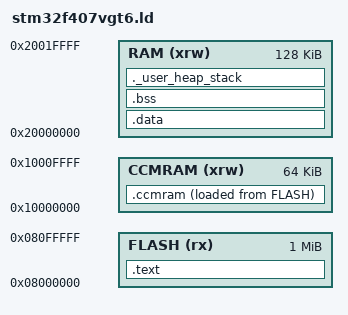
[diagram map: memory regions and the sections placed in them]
/*
******************************************************************************
**

**  File        : LinkerScript.ld
**
**  Author		: Auto-generated by System Workbench for STM32
**
**  Abstract    : Linker script for STM32F407VGTx series
**                1024Kbytes FLASH and 192Kbytes RAM
**
**                Set heap size, stack size and stack location according
**                to application requirements.
**
**                Set memory bank area and size if external memory is used.
**
**  Target      : STMicroelectronics STM32
**
**  Distribution: The file is distributed “as is,” without any warranty
**                of any kind.
**
*****************************************************************************
** @attention
**
** <h2><center>&copy; COPYRIGHT(c) 2019 STMicroelectronics</center></h2>
**
** Redistribution and use in source and binary forms, with or without modification,
** are permitted provided that the following conditions are met:
**   1. Redistributions of source code must retain the above copyright notice,
**      this list of conditions and the following disclaimer.
**   2. Redistributions in binary form must reproduce the above copyright notice,
**      this list of conditions and the following disclaimer in the documentation
**      and/or other materials provided with the distribution.
**   3. Neither the name of STMicroelectronics nor the names of its contributors
**      may be used to endorse or promote products derived from this software
**      without specific prior written permission.
**
** THIS SOFTWARE IS PROVIDED BY THE COPYRIGHT HOLDERS AND CONTRIBUTORS "AS IS"
** AND ANY EXPRESS OR IMPLIED WARRANTIES, INCLUDING, BUT NOT LIMITED TO, THE
** IMPLIED WARRANTIES OF MERCHANTABILITY AND FITNESS FOR A PARTICULAR PURPOSE ARE
** DISCLAIMED. IN NO EVENT SHALL THE COPYRIGHT HOLDER OR CONTRIBUTORS BE LIABLE
** FOR ANY DIRECT, INDIRECT, INCIDENTAL, SPECIAL, EXEMPLARY, OR CONSEQUENTIAL
** DAMAGES (INCLUDING, BUT NOT LIMITED TO, PROCUREMENT OF SUBSTITUTE GOODS OR
** SERVICES; LOSS OF USE, DATA, OR PROFITS; OR BUSINESS INTERRUPTION) HOWEVER
** CAUSED AND ON ANY THEORY OF LIABILITY, WHETHER IN CONTRACT, STRICT LIABILITY,
** OR TORT (INCLUDING NEGLIGENCE OR OTHERWISE) ARISING IN ANY WAY OUT OF THE USE
** OF THIS SOFTWARE, EVEN IF ADVISED OF THE POSSIBILITY OF SUCH DAMAGE.
**
*****************************************************************************
*/

/* Entry Point */
ENTRY(Reset_Handler)

/* Highest address of the user mode stack */
_estack = 0x20020000;    /* end of RAM */
/* Generate a link error if heap and stack don't fit into RAM */
_Min_Heap_Size = 0x200;      /* required amount of heap  */
_Min_Stack_Size = 0x400; /* required amount of stack */

/* Specify the memory areas */
MEMORY
{
RAM (xrw)      : ORIGIN = 0x20000000, LENGTH = 128K
CCMRAM (xrw)      : ORIGIN = 0x10000000, LENGTH = 64K
FLASH (rx)      : ORIGIN = 0x8000000, LENGTH = 1024K
}

/* Define output sections */
SECTIONS
{
    .text :
    {
        . = ALIGN(4);

        _text = .;

        KEEP(*(.isr_vector))

        . = ALIGN(4);
        
        *(.text .text* .gnu.linkonce.t.*)

        *(.glue_7t) *(.glue_7)

        *(.rodata .rodata* .gnu.linkonce.r.*)

        *(.ARM.extab* .gnu.linkonce.armextab.*)

        . = ALIGN(4);

        KEEP(*(.init))

        . = ALIGN(4);

        __preinit_array_start = .;

        KEEP (*(SORT(.preinit_array*)))

        KEEP (*(.preinit_array))

        __preinit_array_end = .;

        . = ALIGN(4);

        __init_array_start = .;

        KEEP (*(SORT(.init_array.*)))

        KEEP (*(.init_array))

        __init_array_end = .;
        
        /* 
         * FIXME: how useful are global c++ destructors? The application is
         * just going away. Would them be important if they are shutting down
         * something critical?
         */
       
        . = ALIGN(4);

        KEEP(*(.fini))

        . = ALIGN(4);

        __fini_array_start = .;

        KEEP (*(.fini_array))

        KEEP (*(SORT(.fini_array.*)))

        __fini_array_end = .;

        . = ALIGN(4);

        _etext = .;

  } >FLASH

  /* used by the startup to initialize data */
  _sidata = LOADADDR(.data);

  /* Initialized data sections goes into RAM, load LMA copy after code */
  .data : AT(ADDR(.text) + SIZEOF(.text))
  {
    . = ALIGN(4);
    _sdata = .;        /* create a global symbol at data start */
    *(.data)           /* .data sections */
    *(.data*)          /* .data* sections */

    . = ALIGN(4);
    _edata = .;        /* define a global symbol at data end */
  } > RAM

  _siccmram = LOADADDR(.ccmram);

  /* CCM-RAM section 
  * 
  * IMPORTANT NOTE! 
  * If initialized variables will be placed in this section,
  * the startup code needs to be modified to copy the init-values.  
  */
  .ccmram :
  {
    . = ALIGN(4);
    _sccmram = .;       /* create a global symbol at ccmram start */
    *(.ccmram)
    *(.ccmram*)
    
    . = ALIGN(4);
    _eccmram = .;       /* create a global symbol at ccmram end */
  } >CCMRAM AT> FLASH

  
  /* Uninitialized data section */
  . = ALIGN(4);
  .bss :
  {
    /* This is used by the startup in order to initialize the .bss secion */
    _sbss = .;         /* define a global symbol at bss start */
    __bss_start__ = _sbss;
    *(.bss)
    *(.bss*)
    *(COMMON)

    . = ALIGN(4);
    _ebss = .;         /* define a global symbol at bss end */
    __bss_end__ = _ebss;
  } >RAM

  /* User_heap_stack section, used to check that there is enough RAM left */
  ._user_heap_stack :
  {
    . = ALIGN(8);
    PROVIDE ( end = . );
    PROVIDE ( _end = . );
    . = . + _Min_Heap_Size;
    . = . + _Min_Stack_Size;
    . = ALIGN(8);
  } >RAM

  

  /* Remove information from the standard libraries */
  /DISCARD/ :
  {
    libc.a ( * )
    libm.a ( * )
    libgcc.a ( * )
  }

  .ARM.attributes 0 : { *(.ARM.attributes) }
}


